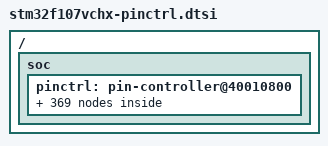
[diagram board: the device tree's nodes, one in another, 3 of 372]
/*
 * NOTE: Autogenerated file using genpinctrl.py
 *
 * SPDX-License-Identifier: Apache-2.0
 */

#include <zephyr/dt-bindings/pinctrl/stm32f1-pinctrl.h>

/ {
	soc {
		pinctrl: pin-controller@40010800 {

			/* ADC_IN */

			/omit-if-no-ref/ adc1_in0_pa0: adc1_in0_pa0 {
				pinmux = <STM32F1_PINMUX('A', 0, ANALOG, NO_REMAP)>;
			};

			/omit-if-no-ref/ adc1_in1_pa1: adc1_in1_pa1 {
				pinmux = <STM32F1_PINMUX('A', 1, ANALOG, NO_REMAP)>;
			};

			/omit-if-no-ref/ adc1_in2_pa2: adc1_in2_pa2 {
				pinmux = <STM32F1_PINMUX('A', 2, ANALOG, NO_REMAP)>;
			};

			/omit-if-no-ref/ adc1_in3_pa3: adc1_in3_pa3 {
				pinmux = <STM32F1_PINMUX('A', 3, ANALOG, NO_REMAP)>;
			};

			/omit-if-no-ref/ adc1_in4_pa4: adc1_in4_pa4 {
				pinmux = <STM32F1_PINMUX('A', 4, ANALOG, NO_REMAP)>;
			};

			/omit-if-no-ref/ adc1_in5_pa5: adc1_in5_pa5 {
				pinmux = <STM32F1_PINMUX('A', 5, ANALOG, NO_REMAP)>;
			};

			/omit-if-no-ref/ adc1_in6_pa6: adc1_in6_pa6 {
				pinmux = <STM32F1_PINMUX('A', 6, ANALOG, NO_REMAP)>;
			};

			/omit-if-no-ref/ adc1_in7_pa7: adc1_in7_pa7 {
				pinmux = <STM32F1_PINMUX('A', 7, ANALOG, NO_REMAP)>;
			};

			/omit-if-no-ref/ adc1_in8_pb0: adc1_in8_pb0 {
				pinmux = <STM32F1_PINMUX('B', 0, ANALOG, NO_REMAP)>;
			};

			/omit-if-no-ref/ adc1_in9_pb1: adc1_in9_pb1 {
				pinmux = <STM32F1_PINMUX('B', 1, ANALOG, NO_REMAP)>;
			};

			/omit-if-no-ref/ adc1_in10_pc0: adc1_in10_pc0 {
				pinmux = <STM32F1_PINMUX('C', 0, ANALOG, NO_REMAP)>;
			};

			/omit-if-no-ref/ adc1_in11_pc1: adc1_in11_pc1 {
				pinmux = <STM32F1_PINMUX('C', 1, ANALOG, NO_REMAP)>;
			};

			/omit-if-no-ref/ adc1_in12_pc2: adc1_in12_pc2 {
				pinmux = <STM32F1_PINMUX('C', 2, ANALOG, NO_REMAP)>;
			};

			/omit-if-no-ref/ adc1_in13_pc3: adc1_in13_pc3 {
				pinmux = <STM32F1_PINMUX('C', 3, ANALOG, NO_REMAP)>;
			};

			/omit-if-no-ref/ adc1_in14_pc4: adc1_in14_pc4 {
				pinmux = <STM32F1_PINMUX('C', 4, ANALOG, NO_REMAP)>;
			};

			/omit-if-no-ref/ adc1_in15_pc5: adc1_in15_pc5 {
				pinmux = <STM32F1_PINMUX('C', 5, ANALOG, NO_REMAP)>;
			};

			/omit-if-no-ref/ adc2_in0_pa0: adc2_in0_pa0 {
				pinmux = <STM32F1_PINMUX('A', 0, ANALOG, NO_REMAP)>;
			};

			/omit-if-no-ref/ adc2_in1_pa1: adc2_in1_pa1 {
				pinmux = <STM32F1_PINMUX('A', 1, ANALOG, NO_REMAP)>;
			};

			/omit-if-no-ref/ adc2_in2_pa2: adc2_in2_pa2 {
				pinmux = <STM32F1_PINMUX('A', 2, ANALOG, NO_REMAP)>;
			};

			/omit-if-no-ref/ adc2_in3_pa3: adc2_in3_pa3 {
				pinmux = <STM32F1_PINMUX('A', 3, ANALOG, NO_REMAP)>;
			};

			/omit-if-no-ref/ adc2_in4_pa4: adc2_in4_pa4 {
				pinmux = <STM32F1_PINMUX('A', 4, ANALOG, NO_REMAP)>;
			};

			/omit-if-no-ref/ adc2_in5_pa5: adc2_in5_pa5 {
				pinmux = <STM32F1_PINMUX('A', 5, ANALOG, NO_REMAP)>;
			};

			/omit-if-no-ref/ adc2_in6_pa6: adc2_in6_pa6 {
				pinmux = <STM32F1_PINMUX('A', 6, ANALOG, NO_REMAP)>;
			};

			/omit-if-no-ref/ adc2_in7_pa7: adc2_in7_pa7 {
				pinmux = <STM32F1_PINMUX('A', 7, ANALOG, NO_REMAP)>;
			};

			/omit-if-no-ref/ adc2_in8_pb0: adc2_in8_pb0 {
				pinmux = <STM32F1_PINMUX('B', 0, ANALOG, NO_REMAP)>;
			};

			/omit-if-no-ref/ adc2_in9_pb1: adc2_in9_pb1 {
				pinmux = <STM32F1_PINMUX('B', 1, ANALOG, NO_REMAP)>;
			};

			/omit-if-no-ref/ adc2_in10_pc0: adc2_in10_pc0 {
				pinmux = <STM32F1_PINMUX('C', 0, ANALOG, NO_REMAP)>;
			};

			/omit-if-no-ref/ adc2_in11_pc1: adc2_in11_pc1 {
				pinmux = <STM32F1_PINMUX('C', 1, ANALOG, NO_REMAP)>;
			};

			/omit-if-no-ref/ adc2_in12_pc2: adc2_in12_pc2 {
				pinmux = <STM32F1_PINMUX('C', 2, ANALOG, NO_REMAP)>;
			};

			/omit-if-no-ref/ adc2_in13_pc3: adc2_in13_pc3 {
				pinmux = <STM32F1_PINMUX('C', 3, ANALOG, NO_REMAP)>;
			};

			/omit-if-no-ref/ adc2_in14_pc4: adc2_in14_pc4 {
				pinmux = <STM32F1_PINMUX('C', 4, ANALOG, NO_REMAP)>;
			};

			/omit-if-no-ref/ adc2_in15_pc5: adc2_in15_pc5 {
				pinmux = <STM32F1_PINMUX('C', 5, ANALOG, NO_REMAP)>;
			};

			/* Analog */

			/omit-if-no-ref/ analog_pa0: analog_pa0 {
				pinmux = <STM32F1_PINMUX('A', 0, ANALOG, NO_REMAP)>;
			};

			/omit-if-no-ref/ analog_pa1: analog_pa1 {
				pinmux = <STM32F1_PINMUX('A', 1, ANALOG, NO_REMAP)>;
			};

			/omit-if-no-ref/ analog_pa2: analog_pa2 {
				pinmux = <STM32F1_PINMUX('A', 2, ANALOG, NO_REMAP)>;
			};

			/omit-if-no-ref/ analog_pa3: analog_pa3 {
				pinmux = <STM32F1_PINMUX('A', 3, ANALOG, NO_REMAP)>;
			};

			/omit-if-no-ref/ analog_pa4: analog_pa4 {
				pinmux = <STM32F1_PINMUX('A', 4, ANALOG, NO_REMAP)>;
			};

			/omit-if-no-ref/ analog_pa5: analog_pa5 {
				pinmux = <STM32F1_PINMUX('A', 5, ANALOG, NO_REMAP)>;
			};

			/omit-if-no-ref/ analog_pa6: analog_pa6 {
				pinmux = <STM32F1_PINMUX('A', 6, ANALOG, NO_REMAP)>;
			};

			/omit-if-no-ref/ analog_pa7: analog_pa7 {
				pinmux = <STM32F1_PINMUX('A', 7, ANALOG, NO_REMAP)>;
			};

			/omit-if-no-ref/ analog_pa8: analog_pa8 {
				pinmux = <STM32F1_PINMUX('A', 8, ANALOG, NO_REMAP)>;
			};

			/omit-if-no-ref/ analog_pa9: analog_pa9 {
				pinmux = <STM32F1_PINMUX('A', 9, ANALOG, NO_REMAP)>;
			};

			/omit-if-no-ref/ analog_pa10: analog_pa10 {
				pinmux = <STM32F1_PINMUX('A', 10, ANALOG, NO_REMAP)>;
			};

			/omit-if-no-ref/ analog_pa11: analog_pa11 {
				pinmux = <STM32F1_PINMUX('A', 11, ANALOG, NO_REMAP)>;
			};

			/omit-if-no-ref/ analog_pa12: analog_pa12 {
				pinmux = <STM32F1_PINMUX('A', 12, ANALOG, NO_REMAP)>;
			};

			/omit-if-no-ref/ analog_pa13: analog_pa13 {
				pinmux = <STM32F1_PINMUX('A', 13, ANALOG, NO_REMAP)>;
			};

			/omit-if-no-ref/ analog_pa14: analog_pa14 {
				pinmux = <STM32F1_PINMUX('A', 14, ANALOG, NO_REMAP)>;
			};

			/omit-if-no-ref/ analog_pa15: analog_pa15 {
				pinmux = <STM32F1_PINMUX('A', 15, ANALOG, NO_REMAP)>;
			};

			/omit-if-no-ref/ analog_pb0: analog_pb0 {
				pinmux = <STM32F1_PINMUX('B', 0, ANALOG, NO_REMAP)>;
			};

			/omit-if-no-ref/ analog_pb1: analog_pb1 {
				pinmux = <STM32F1_PINMUX('B', 1, ANALOG, NO_REMAP)>;
			};

			/omit-if-no-ref/ analog_pb2: analog_pb2 {
				pinmux = <STM32F1_PINMUX('B', 2, ANALOG, NO_REMAP)>;
			};

			/omit-if-no-ref/ analog_pb3: analog_pb3 {
				pinmux = <STM32F1_PINMUX('B', 3, ANALOG, NO_REMAP)>;
			};

			/omit-if-no-ref/ analog_pb4: analog_pb4 {
				pinmux = <STM32F1_PINMUX('B', 4, ANALOG, NO_REMAP)>;
			};

			/omit-if-no-ref/ analog_pb5: analog_pb5 {
				pinmux = <STM32F1_PINMUX('B', 5, ANALOG, NO_REMAP)>;
			};

			/omit-if-no-ref/ analog_pb6: analog_pb6 {
				pinmux = <STM32F1_PINMUX('B', 6, ANALOG, NO_REMAP)>;
			};

			/omit-if-no-ref/ analog_pb7: analog_pb7 {
				pinmux = <STM32F1_PINMUX('B', 7, ANALOG, NO_REMAP)>;
			};

			/omit-if-no-ref/ analog_pb8: analog_pb8 {
				pinmux = <STM32F1_PINMUX('B', 8, ANALOG, NO_REMAP)>;
			};

			/omit-if-no-ref/ analog_pb9: analog_pb9 {
				pinmux = <STM32F1_PINMUX('B', 9, ANALOG, NO_REMAP)>;
			};

			/omit-if-no-ref/ analog_pb10: analog_pb10 {
				pinmux = <STM32F1_PINMUX('B', 10, ANALOG, NO_REMAP)>;
			};

			/omit-if-no-ref/ analog_pb11: analog_pb11 {
				pinmux = <STM32F1_PINMUX('B', 11, ANALOG, NO_REMAP)>;
			};

			/omit-if-no-ref/ analog_pb12: analog_pb12 {
				pinmux = <STM32F1_PINMUX('B', 12, ANALOG, NO_REMAP)>;
			};

			/omit-if-no-ref/ analog_pb13: analog_pb13 {
				pinmux = <STM32F1_PINMUX('B', 13, ANALOG, NO_REMAP)>;
			};

			/omit-if-no-ref/ analog_pb14: analog_pb14 {
				pinmux = <STM32F1_PINMUX('B', 14, ANALOG, NO_REMAP)>;
			};

			/omit-if-no-ref/ analog_pb15: analog_pb15 {
				pinmux = <STM32F1_PINMUX('B', 15, ANALOG, NO_REMAP)>;
			};

			/omit-if-no-ref/ analog_pc0: analog_pc0 {
				pinmux = <STM32F1_PINMUX('C', 0, ANALOG, NO_REMAP)>;
			};

			/omit-if-no-ref/ analog_pc1: analog_pc1 {
				pinmux = <STM32F1_PINMUX('C', 1, ANALOG, NO_REMAP)>;
			};

			/omit-if-no-ref/ analog_pc2: analog_pc2 {
				pinmux = <STM32F1_PINMUX('C', 2, ANALOG, NO_REMAP)>;
			};

			/omit-if-no-ref/ analog_pc3: analog_pc3 {
				pinmux = <STM32F1_PINMUX('C', 3, ANALOG, NO_REMAP)>;
			};

			/omit-if-no-ref/ analog_pc4: analog_pc4 {
				pinmux = <STM32F1_PINMUX('C', 4, ANALOG, NO_REMAP)>;
			};

			/omit-if-no-ref/ analog_pc5: analog_pc5 {
				pinmux = <STM32F1_PINMUX('C', 5, ANALOG, NO_REMAP)>;
			};

			/omit-if-no-ref/ analog_pc6: analog_pc6 {
				pinmux = <STM32F1_PINMUX('C', 6, ANALOG, NO_REMAP)>;
			};

			/omit-if-no-ref/ analog_pc7: analog_pc7 {
				pinmux = <STM32F1_PINMUX('C', 7, ANALOG, NO_REMAP)>;
			};

			/omit-if-no-ref/ analog_pc8: analog_pc8 {
				pinmux = <STM32F1_PINMUX('C', 8, ANALOG, NO_REMAP)>;
			};

			/omit-if-no-ref/ analog_pc9: analog_pc9 {
				pinmux = <STM32F1_PINMUX('C', 9, ANALOG, NO_REMAP)>;
			};

			/omit-if-no-ref/ analog_pc10: analog_pc10 {
				pinmux = <STM32F1_PINMUX('C', 10, ANALOG, NO_REMAP)>;
			};

			/omit-if-no-ref/ analog_pc11: analog_pc11 {
				pinmux = <STM32F1_PINMUX('C', 11, ANALOG, NO_REMAP)>;
			};

			/omit-if-no-ref/ analog_pc12: analog_pc12 {
				pinmux = <STM32F1_PINMUX('C', 12, ANALOG, NO_REMAP)>;
			};

			/omit-if-no-ref/ analog_pc13: analog_pc13 {
				pinmux = <STM32F1_PINMUX('C', 13, ANALOG, NO_REMAP)>;
			};

			/omit-if-no-ref/ analog_pc14: analog_pc14 {
				pinmux = <STM32F1_PINMUX('C', 14, ANALOG, NO_REMAP)>;
			};

			/omit-if-no-ref/ analog_pc15: analog_pc15 {
				pinmux = <STM32F1_PINMUX('C', 15, ANALOG, NO_REMAP)>;
			};

			/omit-if-no-ref/ analog_pd0: analog_pd0 {
				pinmux = <STM32F1_PINMUX('D', 0, ANALOG, NO_REMAP)>;
			};

			/omit-if-no-ref/ analog_pd1: analog_pd1 {
				pinmux = <STM32F1_PINMUX('D', 1, ANALOG, NO_REMAP)>;
			};

			/omit-if-no-ref/ analog_pd2: analog_pd2 {
				pinmux = <STM32F1_PINMUX('D', 2, ANALOG, NO_REMAP)>;
			};

			/omit-if-no-ref/ analog_pd3: analog_pd3 {
				pinmux = <STM32F1_PINMUX('D', 3, ANALOG, NO_REMAP)>;
			};

			/omit-if-no-ref/ analog_pd4: analog_pd4 {
				pinmux = <STM32F1_PINMUX('D', 4, ANALOG, NO_REMAP)>;
			};

			/omit-if-no-ref/ analog_pd5: analog_pd5 {
				pinmux = <STM32F1_PINMUX('D', 5, ANALOG, NO_REMAP)>;
			};

			/omit-if-no-ref/ analog_pd6: analog_pd6 {
				pinmux = <STM32F1_PINMUX('D', 6, ANALOG, NO_REMAP)>;
			};

			/omit-if-no-ref/ analog_pd7: analog_pd7 {
				pinmux = <STM32F1_PINMUX('D', 7, ANALOG, NO_REMAP)>;
			};

			/omit-if-no-ref/ analog_pd8: analog_pd8 {
				pinmux = <STM32F1_PINMUX('D', 8, ANALOG, NO_REMAP)>;
			};

			/omit-if-no-ref/ analog_pd9: analog_pd9 {
				pinmux = <STM32F1_PINMUX('D', 9, ANALOG, NO_REMAP)>;
			};

			/omit-if-no-ref/ analog_pd10: analog_pd10 {
				pinmux = <STM32F1_PINMUX('D', 10, ANALOG, NO_REMAP)>;
			};

			/omit-if-no-ref/ analog_pd11: analog_pd11 {
				pinmux = <STM32F1_PINMUX('D', 11, ANALOG, NO_REMAP)>;
			};

			/omit-if-no-ref/ analog_pd12: analog_pd12 {
				pinmux = <STM32F1_PINMUX('D', 12, ANALOG, NO_REMAP)>;
			};

			/omit-if-no-ref/ analog_pd13: analog_pd13 {
				pinmux = <STM32F1_PINMUX('D', 13, ANALOG, NO_REMAP)>;
			};

			/omit-if-no-ref/ analog_pd14: analog_pd14 {
				pinmux = <STM32F1_PINMUX('D', 14, ANALOG, NO_REMAP)>;
			};

			/omit-if-no-ref/ analog_pd15: analog_pd15 {
				pinmux = <STM32F1_PINMUX('D', 15, ANALOG, NO_REMAP)>;
			};

			/omit-if-no-ref/ analog_pe0: analog_pe0 {
				pinmux = <STM32F1_PINMUX('E', 0, ANALOG, NO_REMAP)>;
			};

			/omit-if-no-ref/ analog_pe1: analog_pe1 {
				pinmux = <STM32F1_PINMUX('E', 1, ANALOG, NO_REMAP)>;
			};

			/omit-if-no-ref/ analog_pe2: analog_pe2 {
				pinmux = <STM32F1_PINMUX('E', 2, ANALOG, NO_REMAP)>;
			};

			/omit-if-no-ref/ analog_pe3: analog_pe3 {
				pinmux = <STM32F1_PINMUX('E', 3, ANALOG, NO_REMAP)>;
			};

			/omit-if-no-ref/ analog_pe4: analog_pe4 {
				pinmux = <STM32F1_PINMUX('E', 4, ANALOG, NO_REMAP)>;
			};

			/omit-if-no-ref/ analog_pe5: analog_pe5 {
				pinmux = <STM32F1_PINMUX('E', 5, ANALOG, NO_REMAP)>;
			};

			/omit-if-no-ref/ analog_pe6: analog_pe6 {
				pinmux = <STM32F1_PINMUX('E', 6, ANALOG, NO_REMAP)>;
			};

			/omit-if-no-ref/ analog_pe7: analog_pe7 {
				pinmux = <STM32F1_PINMUX('E', 7, ANALOG, NO_REMAP)>;
			};

			/omit-if-no-ref/ analog_pe8: analog_pe8 {
				pinmux = <STM32F1_PINMUX('E', 8, ANALOG, NO_REMAP)>;
			};

			/omit-if-no-ref/ analog_pe9: analog_pe9 {
				pinmux = <STM32F1_PINMUX('E', 9, ANALOG, NO_REMAP)>;
			};

			/omit-if-no-ref/ analog_pe10: analog_pe10 {
				pinmux = <STM32F1_PINMUX('E', 10, ANALOG, NO_REMAP)>;
			};

			/omit-if-no-ref/ analog_pe11: analog_pe11 {
				pinmux = <STM32F1_PINMUX('E', 11, ANALOG, NO_REMAP)>;
			};

			/omit-if-no-ref/ analog_pe12: analog_pe12 {
				pinmux = <STM32F1_PINMUX('E', 12, ANALOG, NO_REMAP)>;
			};

			/omit-if-no-ref/ analog_pe13: analog_pe13 {
				pinmux = <STM32F1_PINMUX('E', 13, ANALOG, NO_REMAP)>;
			};

			/omit-if-no-ref/ analog_pe14: analog_pe14 {
				pinmux = <STM32F1_PINMUX('E', 14, ANALOG, NO_REMAP)>;
			};

			/omit-if-no-ref/ analog_pe15: analog_pe15 {
				pinmux = <STM32F1_PINMUX('E', 15, ANALOG, NO_REMAP)>;
			};

			/* CAN_RX */

			/omit-if-no-ref/ can1_rx_pa11: can1_rx_pa11 {
				pinmux = <STM32F1_PINMUX('A', 11, GPIO_IN, CAN1_REMAP0)>;
			};

			/omit-if-no-ref/ can1_rx_remap1_pb8: can1_rx_remap1_pb8 {
				pinmux = <STM32F1_PINMUX('B', 8, GPIO_IN, CAN1_REMAP1)>;
			};

			/omit-if-no-ref/ can1_rx_remap2_pd0: can1_rx_remap2_pd0 {
				pinmux = <STM32F1_PINMUX('D', 0, GPIO_IN, CAN1_REMAP2)>;
			};

			/omit-if-no-ref/ can2_rx_remap1_pb5: can2_rx_remap1_pb5 {
				pinmux = <STM32F1_PINMUX('B', 5, GPIO_IN, CAN2_REMAP1)>;
			};

			/omit-if-no-ref/ can2_rx_pb12: can2_rx_pb12 {
				pinmux = <STM32F1_PINMUX('B', 12, GPIO_IN, CAN2_REMAP0)>;
			};

			/* CAN_TX */

			/omit-if-no-ref/ can1_tx_pa12: can1_tx_pa12 {
				pinmux = <STM32F1_PINMUX('A', 12, ALTERNATE, CAN1_REMAP0)>;
			};

			/omit-if-no-ref/ can1_tx_remap1_pb9: can1_tx_remap1_pb9 {
				pinmux = <STM32F1_PINMUX('B', 9, ALTERNATE, CAN1_REMAP1)>;
			};

			/omit-if-no-ref/ can1_tx_remap2_pd1: can1_tx_remap2_pd1 {
				pinmux = <STM32F1_PINMUX('D', 1, ALTERNATE, CAN1_REMAP2)>;
			};

			/omit-if-no-ref/ can2_tx_remap1_pb6: can2_tx_remap1_pb6 {
				pinmux = <STM32F1_PINMUX('B', 6, ALTERNATE, CAN2_REMAP1)>;
			};

			/omit-if-no-ref/ can2_tx_pb13: can2_tx_pb13 {
				pinmux = <STM32F1_PINMUX('B', 13, ALTERNATE, CAN2_REMAP0)>;
			};

			/* DAC_OUT */

			/omit-if-no-ref/ dac_out1_pa4: dac_out1_pa4 {
				pinmux = <STM32F1_PINMUX('A', 4, ANALOG, NO_REMAP)>;
			};

			/omit-if-no-ref/ dac_out2_pa5: dac_out2_pa5 {
				pinmux = <STM32F1_PINMUX('A', 5, ANALOG, NO_REMAP)>;
			};

			/* ETH_COL */

			/omit-if-no-ref/ eth_col_pa3: eth_col_pa3 {
				pinmux = <STM32F1_PINMUX('A', 3, GPIO_IN, NO_REMAP)>;
			};

			/* ETH_CRS */

			/omit-if-no-ref/ eth_crs_pa0: eth_crs_pa0 {
				pinmux = <STM32F1_PINMUX('A', 0, GPIO_IN, NO_REMAP)>;
			};

			/* ETH_CRS_DV */

			/omit-if-no-ref/ eth_crs_dv_pa7: eth_crs_dv_pa7 {
				pinmux = <STM32F1_PINMUX('A', 7, GPIO_IN, ETH_REMAP0)>;
			};

			/omit-if-no-ref/ eth_crs_dv_remap1_pd8: eth_crs_dv_remap1_pd8 {
				pinmux = <STM32F1_PINMUX('D', 8, GPIO_IN, ETH_REMAP1)>;
			};

			/* ETH_MDC */

			/omit-if-no-ref/ eth_mdc_pc1: eth_mdc_pc1 {
				pinmux = <STM32F1_PINMUX('C', 1, ALTERNATE, NO_REMAP)>;
				slew-rate = "max-speed-50mhz";
			};

			/* ETH_MDIO */

			/omit-if-no-ref/ eth_mdio_pa2: eth_mdio_pa2 {
				pinmux = <STM32F1_PINMUX('A', 2, ALTERNATE, NO_REMAP)>;
				slew-rate = "max-speed-50mhz";
			};

			/* ETH_PPS_OUT */

			/omit-if-no-ref/ eth_pps_out_pb5: eth_pps_out_pb5 {
				pinmux = <STM32F1_PINMUX('B', 5, ALTERNATE, NO_REMAP)>;
				slew-rate = "max-speed-50mhz";
			};

			/* ETH_REF_CLK */

			/omit-if-no-ref/ eth_ref_clk_pa1: eth_ref_clk_pa1 {
				pinmux = <STM32F1_PINMUX('A', 1, GPIO_IN, NO_REMAP)>;
			};

			/* ETH_RXD0 */

			/omit-if-no-ref/ eth_rxd0_pc4: eth_rxd0_pc4 {
				pinmux = <STM32F1_PINMUX('C', 4, GPIO_IN, ETH_REMAP0)>;
			};

			/omit-if-no-ref/ eth_rxd0_remap1_pd9: eth_rxd0_remap1_pd9 {
				pinmux = <STM32F1_PINMUX('D', 9, GPIO_IN, ETH_REMAP1)>;
			};

			/* ETH_RXD1 */

			/omit-if-no-ref/ eth_rxd1_pc5: eth_rxd1_pc5 {
				pinmux = <STM32F1_PINMUX('C', 5, GPIO_IN, ETH_REMAP0)>;
			};

			/omit-if-no-ref/ eth_rxd1_remap1_pd10: eth_rxd1_remap1_pd10 {
				pinmux = <STM32F1_PINMUX('D', 10, GPIO_IN, ETH_REMAP1)>;
			};

			/* ETH_RXD2 */

			/omit-if-no-ref/ eth_rxd2_pb0: eth_rxd2_pb0 {
				pinmux = <STM32F1_PINMUX('B', 0, GPIO_IN, ETH_REMAP0)>;
			};

			/omit-if-no-ref/ eth_rxd2_remap1_pd11: eth_rxd2_remap1_pd11 {
				pinmux = <STM32F1_PINMUX('D', 11, GPIO_IN, ETH_REMAP1)>;
			};

			/* ETH_RXD3 */

			/omit-if-no-ref/ eth_rxd3_pb1: eth_rxd3_pb1 {
				pinmux = <STM32F1_PINMUX('B', 1, GPIO_IN, ETH_REMAP0)>;
			};

			/omit-if-no-ref/ eth_rxd3_remap1_pd12: eth_rxd3_remap1_pd12 {
				pinmux = <STM32F1_PINMUX('D', 12, GPIO_IN, ETH_REMAP1)>;
			};

			/* ETH_RX_CLK */

			/omit-if-no-ref/ eth_rx_clk_pa1: eth_rx_clk_pa1 {
				pinmux = <STM32F1_PINMUX('A', 1, GPIO_IN, NO_REMAP)>;
			};

			/* ETH_RX_DV */

			/omit-if-no-ref/ eth_rx_dv_pa7: eth_rx_dv_pa7 {
				pinmux = <STM32F1_PINMUX('A', 7, GPIO_IN, ETH_REMAP0)>;
			};

			/omit-if-no-ref/ eth_rx_dv_remap1_pd8: eth_rx_dv_remap1_pd8 {
				pinmux = <STM32F1_PINMUX('D', 8, GPIO_IN, ETH_REMAP1)>;
			};

			/* ETH_RX_ER */

			/omit-if-no-ref/ eth_rx_er_pb10: eth_rx_er_pb10 {
				pinmux = <STM32F1_PINMUX('B', 10, GPIO_IN, NO_REMAP)>;
			};

			/* ETH_TXD0 */

			/omit-if-no-ref/ eth_txd0_pb12: eth_txd0_pb12 {
				pinmux = <STM32F1_PINMUX('B', 12, ALTERNATE, NO_REMAP)>;
				slew-rate = "max-speed-50mhz";
			};

			/* ETH_TXD1 */

			/omit-if-no-ref/ eth_txd1_pb13: eth_txd1_pb13 {
				pinmux = <STM32F1_PINMUX('B', 13, ALTERNATE, NO_REMAP)>;
				slew-rate = "max-speed-50mhz";
			};

			/* ETH_TXD2 */

			/omit-if-no-ref/ eth_txd2_pc2: eth_txd2_pc2 {
				pinmux = <STM32F1_PINMUX('C', 2, ALTERNATE, NO_REMAP)>;
				slew-rate = "max-speed-50mhz";
			};

			/* ETH_TXD3 */

			/omit-if-no-ref/ eth_txd3_pb8: eth_txd3_pb8 {
				pinmux = <STM32F1_PINMUX('B', 8, ALTERNATE, NO_REMAP)>;
				slew-rate = "max-speed-50mhz";
			};

			/* ETH_TX_CLK */

			/omit-if-no-ref/ eth_tx_clk_pc3: eth_tx_clk_pc3 {
				pinmux = <STM32F1_PINMUX('C', 3, GPIO_IN, NO_REMAP)>;
			};

			/* ETH_TX_EN */

			/omit-if-no-ref/ eth_tx_en_pb11: eth_tx_en_pb11 {
				pinmux = <STM32F1_PINMUX('B', 11, ALTERNATE, NO_REMAP)>;
				slew-rate = "max-speed-50mhz";
			};

			/* I2C_SCL */

			/omit-if-no-ref/ i2c1_scl_pb6: i2c1_scl_pb6 {
				pinmux = <STM32F1_PINMUX('B', 6, ALTERNATE, I2C1_REMAP0)>;
				drive-open-drain;
			};

			/omit-if-no-ref/ i2c1_scl_remap1_pb8: i2c1_scl_remap1_pb8 {
				pinmux = <STM32F1_PINMUX('B', 8, ALTERNATE, I2C1_REMAP1)>;
				drive-open-drain;
			};

			/* I2C_SDA */

			/omit-if-no-ref/ i2c1_sda_pb7: i2c1_sda_pb7 {
				pinmux = <STM32F1_PINMUX('B', 7, ALTERNATE, I2C1_REMAP0)>;
				drive-open-drain;
			};

			/omit-if-no-ref/ i2c1_sda_remap1_pb9: i2c1_sda_remap1_pb9 {
				pinmux = <STM32F1_PINMUX('B', 9, ALTERNATE, I2C1_REMAP1)>;
				drive-open-drain;
			};

			/* I2C_SMBA */

			/omit-if-no-ref/ i2c1_smba_pb5: i2c1_smba_pb5 {
				pinmux = <STM32F1_PINMUX('B', 5, ALTERNATE, NO_REMAP)>;
			};

			/* I2S_CK */

			/omit-if-no-ref/ i2s2_ck_pb13: i2s2_ck_pb13 {
				pinmux = <STM32F1_PINMUX('B', 13, ALTERNATE, NO_REMAP)>;
			};

			/omit-if-no-ref/ i2s3_ck_pb3: i2s3_ck_pb3 {
				pinmux = <STM32F1_PINMUX('B', 3, ALTERNATE, I2S3_REMAP0)>;
			};

			/omit-if-no-ref/ i2s3_ck_remap1_pc10: i2s3_ck_remap1_pc10 {
				pinmux = <STM32F1_PINMUX('C', 10, ALTERNATE, I2S3_REMAP1)>;
			};

			/* I2S_SD */

			/omit-if-no-ref/ i2s2_sd_pb15: i2s2_sd_pb15 {
				pinmux = <STM32F1_PINMUX('B', 15, ALTERNATE, NO_REMAP)>;
			};

			/omit-if-no-ref/ i2s3_sd_pb5: i2s3_sd_pb5 {
				pinmux = <STM32F1_PINMUX('B', 5, ALTERNATE, I2S3_REMAP0)>;
			};

			/omit-if-no-ref/ i2s3_sd_remap1_pc12: i2s3_sd_remap1_pc12 {
				pinmux = <STM32F1_PINMUX('C', 12, ALTERNATE, I2S3_REMAP1)>;
			};

			/* I2S_WS */

			/omit-if-no-ref/ i2s2_ws_pb12: i2s2_ws_pb12 {
				pinmux = <STM32F1_PINMUX('B', 12, ALTERNATE, NO_REMAP)>;
			};

			/omit-if-no-ref/ i2s3_ws_remap1_pa4: i2s3_ws_remap1_pa4 {
				pinmux = <STM32F1_PINMUX('A', 4, ALTERNATE, I2S3_REMAP1)>;
			};

			/omit-if-no-ref/ i2s3_ws_pa15: i2s3_ws_pa15 {
				pinmux = <STM32F1_PINMUX('A', 15, ALTERNATE, I2S3_REMAP0)>;
			};

			/* JTAG PORT */

			/omit-if-no-ref/ sys_jtms_swdio_pa13: sys_jtms_swdio_pa13 {
				pinmux = <STM32F1_PINMUX('A', 13, ALTERNATE, NO_REMAP)>;
			};

			/omit-if-no-ref/ sys_jtck_swclk_pa14: sys_jtck_swclk_pa14 {
				pinmux = <STM32F1_PINMUX('A', 14, ALTERNATE, NO_REMAP)>;
			};

			/omit-if-no-ref/ sys_jtdi_pa15: sys_jtdi_pa15 {
				pinmux = <STM32F1_PINMUX('A', 15, ALTERNATE, NO_REMAP)>;
			};

			/omit-if-no-ref/ sys_jtdo_pb3: sys_jtdo_pb3 {
				pinmux = <STM32F1_PINMUX('B', 3, ALTERNATE, NO_REMAP)>;
			};

			/* RCC_MCO */

			/omit-if-no-ref/ rcc_mco_pa8: rcc_mco_pa8 {
				pinmux = <STM32F1_PINMUX('A', 8, ALTERNATE, NO_REMAP)>;
			};

			/* SPI_MASTER_MISO */

			/omit-if-no-ref/ spi1_miso_master_pa6: spi1_miso_master_pa6 {
				pinmux = <STM32F1_PINMUX('A', 6, GPIO_IN, SPI1_REMAP0)>;
				bias-pull-down;
			};

			/omit-if-no-ref/ spi1_miso_remap1_master_pb4: spi1_miso_remap1_master_pb4 {
				pinmux = <STM32F1_PINMUX('B', 4, GPIO_IN, SPI1_REMAP1)>;
				bias-pull-down;
			};

			/omit-if-no-ref/ spi2_miso_master_pb14: spi2_miso_master_pb14 {
				pinmux = <STM32F1_PINMUX('B', 14, GPIO_IN, NO_REMAP)>;
				bias-pull-down;
			};

			/omit-if-no-ref/ spi3_miso_master_pb4: spi3_miso_master_pb4 {
				pinmux = <STM32F1_PINMUX('B', 4, GPIO_IN, SPI3_REMAP0)>;
				bias-pull-down;
			};

			/omit-if-no-ref/ spi3_miso_remap1_master_pc11: spi3_miso_remap1_master_pc11 {
				pinmux = <STM32F1_PINMUX('C', 11, GPIO_IN, SPI3_REMAP1)>;
				bias-pull-down;
			};

			/* SPI_MASTER_MOSI */

			/omit-if-no-ref/ spi1_mosi_master_pa7: spi1_mosi_master_pa7 {
				pinmux = <STM32F1_PINMUX('A', 7, ALTERNATE, SPI1_REMAP0)>;
			};

			/omit-if-no-ref/ spi1_mosi_remap1_master_pb5: spi1_mosi_remap1_master_pb5 {
				pinmux = <STM32F1_PINMUX('B', 5, ALTERNATE, SPI1_REMAP1)>;
			};

			/omit-if-no-ref/ spi2_mosi_master_pb15: spi2_mosi_master_pb15 {
				pinmux = <STM32F1_PINMUX('B', 15, ALTERNATE, NO_REMAP)>;
			};

			/omit-if-no-ref/ spi3_mosi_master_pb5: spi3_mosi_master_pb5 {
				pinmux = <STM32F1_PINMUX('B', 5, ALTERNATE, SPI3_REMAP0)>;
			};

			/omit-if-no-ref/ spi3_mosi_remap1_master_pc12: spi3_mosi_remap1_master_pc12 {
				pinmux = <STM32F1_PINMUX('C', 12, ALTERNATE, SPI3_REMAP1)>;
			};

			/* SPI_MASTER_NSS */

			/omit-if-no-ref/ spi1_nss_master_pa4: spi1_nss_master_pa4 {
				pinmux = <STM32F1_PINMUX('A', 4, ALTERNATE, SPI1_REMAP0)>;
			};

			/omit-if-no-ref/ spi1_nss_remap1_master_pa15: spi1_nss_remap1_master_pa15 {
				pinmux = <STM32F1_PINMUX('A', 15, ALTERNATE, SPI1_REMAP1)>;
			};

			/omit-if-no-ref/ spi2_nss_master_pb12: spi2_nss_master_pb12 {
				pinmux = <STM32F1_PINMUX('B', 12, ALTERNATE, NO_REMAP)>;
			};

			/omit-if-no-ref/ spi3_nss_remap1_master_pa4: spi3_nss_remap1_master_pa4 {
				pinmux = <STM32F1_PINMUX('A', 4, ALTERNATE, SPI3_REMAP1)>;
			};

			/omit-if-no-ref/ spi3_nss_master_pa15: spi3_nss_master_pa15 {
				pinmux = <STM32F1_PINMUX('A', 15, ALTERNATE, SPI3_REMAP0)>;
			};

			/* SPI_MASTER_SCK */

			/omit-if-no-ref/ spi1_sck_master_pa5: spi1_sck_master_pa5 {
				pinmux = <STM32F1_PINMUX('A', 5, ALTERNATE, SPI1_REMAP0)>;
			};

			/omit-if-no-ref/ spi1_sck_remap1_master_pb3: spi1_sck_remap1_master_pb3 {
				pinmux = <STM32F1_PINMUX('B', 3, ALTERNATE, SPI1_REMAP1)>;
			};

			/omit-if-no-ref/ spi2_sck_master_pb13: spi2_sck_master_pb13 {
				pinmux = <STM32F1_PINMUX('B', 13, ALTERNATE, NO_REMAP)>;
			};

			/omit-if-no-ref/ spi3_sck_master_pb3: spi3_sck_master_pb3 {
				pinmux = <STM32F1_PINMUX('B', 3, ALTERNATE, SPI3_REMAP0)>;
			};

			/omit-if-no-ref/ spi3_sck_remap1_master_pc10: spi3_sck_remap1_master_pc10 {
				pinmux = <STM32F1_PINMUX('C', 10, ALTERNATE, SPI3_REMAP1)>;
			};

			/* SPI_SLAVE_MISO */

			/omit-if-no-ref/ spi1_miso_slave_pa6: spi1_miso_slave_pa6 {
				pinmux = <STM32F1_PINMUX('A', 6, ALTERNATE, SPI1_REMAP0)>;
			};

			/omit-if-no-ref/ spi1_miso_remap1_slave_pb4: spi1_miso_remap1_slave_pb4 {
				pinmux = <STM32F1_PINMUX('B', 4, ALTERNATE, SPI1_REMAP1)>;
			};

			/omit-if-no-ref/ spi2_miso_slave_pb14: spi2_miso_slave_pb14 {
				pinmux = <STM32F1_PINMUX('B', 14, ALTERNATE, NO_REMAP)>;
			};

			/omit-if-no-ref/ spi3_miso_slave_pb4: spi3_miso_slave_pb4 {
				pinmux = <STM32F1_PINMUX('B', 4, ALTERNATE, SPI3_REMAP0)>;
			};

			/omit-if-no-ref/ spi3_miso_remap1_slave_pc11: spi3_miso_remap1_slave_pc11 {
				pinmux = <STM32F1_PINMUX('C', 11, ALTERNATE, SPI3_REMAP1)>;
			};

			/* SPI_SLAVE_MOSI */

			/omit-if-no-ref/ spi1_mosi_slave_pa7: spi1_mosi_slave_pa7 {
				pinmux = <STM32F1_PINMUX('A', 7, GPIO_IN, SPI1_REMAP0)>;
			};

			/omit-if-no-ref/ spi1_mosi_remap1_slave_pb5: spi1_mosi_remap1_slave_pb5 {
				pinmux = <STM32F1_PINMUX('B', 5, GPIO_IN, SPI1_REMAP1)>;
			};

			/omit-if-no-ref/ spi2_mosi_slave_pb15: spi2_mosi_slave_pb15 {
				pinmux = <STM32F1_PINMUX('B', 15, GPIO_IN, NO_REMAP)>;
			};

			/omit-if-no-ref/ spi3_mosi_slave_pb5: spi3_mosi_slave_pb5 {
				pinmux = <STM32F1_PINMUX('B', 5, GPIO_IN, SPI3_REMAP0)>;
			};

			/omit-if-no-ref/ spi3_mosi_remap1_slave_pc12: spi3_mosi_remap1_slave_pc12 {
				pinmux = <STM32F1_PINMUX('C', 12, GPIO_IN, SPI3_REMAP1)>;
			};

			/* SPI_SLAVE_NSS */

			/omit-if-no-ref/ spi1_nss_slave_pa4: spi1_nss_slave_pa4 {
				pinmux = <STM32F1_PINMUX('A', 4, GPIO_IN, SPI1_REMAP0)>;
				bias-pull-up;
			};

			/omit-if-no-ref/ spi1_nss_remap1_slave_pa15: spi1_nss_remap1_slave_pa15 {
				pinmux = <STM32F1_PINMUX('A', 15, GPIO_IN, SPI1_REMAP1)>;
				bias-pull-up;
			};

			/omit-if-no-ref/ spi2_nss_slave_pb12: spi2_nss_slave_pb12 {
				pinmux = <STM32F1_PINMUX('B', 12, GPIO_IN, NO_REMAP)>;
				bias-pull-up;
			};

			/omit-if-no-ref/ spi3_nss_remap1_slave_pa4: spi3_nss_remap1_slave_pa4 {
				pinmux = <STM32F1_PINMUX('A', 4, GPIO_IN, SPI3_REMAP1)>;
				bias-pull-up;
			};

			/omit-if-no-ref/ spi3_nss_slave_pa15: spi3_nss_slave_pa15 {
				pinmux = <STM32F1_PINMUX('A', 15, GPIO_IN, SPI3_REMAP0)>;
				bias-pull-up;
			};

			/* SPI_SLAVE_SCK */

			/omit-if-no-ref/ spi1_sck_slave_pa5: spi1_sck_slave_pa5 {
				pinmux = <STM32F1_PINMUX('A', 5, GPIO_IN, SPI1_REMAP0)>;
			};

			/omit-if-no-ref/ spi1_sck_remap1_slave_pb3: spi1_sck_remap1_slave_pb3 {
				pinmux = <STM32F1_PINMUX('B', 3, GPIO_IN, SPI1_REMAP1)>;
			};

			/omit-if-no-ref/ spi2_sck_slave_pb13: spi2_sck_slave_pb13 {
				pinmux = <STM32F1_PINMUX('B', 13, GPIO_IN, NO_REMAP)>;
			};

			/omit-if-no-ref/ spi3_sck_slave_pb3: spi3_sck_slave_pb3 {
				pinmux = <STM32F1_PINMUX('B', 3, GPIO_IN, SPI3_REMAP0)>;
			};

			/omit-if-no-ref/ spi3_sck_remap1_slave_pc10: spi3_sck_remap1_slave_pc10 {
				pinmux = <STM32F1_PINMUX('C', 10, GPIO_IN, SPI3_REMAP1)>;
			};

			/* TIM_BKIN */

			/omit-if-no-ref/ tim1_bkin_remap1_pa6: tim1_bkin_remap1_pa6 {
				pinmux = <STM32F1_PINMUX('A', 6, GPIO_IN, TIM1_REMAP1)>;
			};

			/omit-if-no-ref/ tim1_bkin_pb12: tim1_bkin_pb12 {
				pinmux = <STM32F1_PINMUX('B', 12, GPIO_IN, TIM1_REMAP0)>;
			};

			/omit-if-no-ref/ tim1_bkin_remap2_pe15: tim1_bkin_remap2_pe15 {
				pinmux = <STM32F1_PINMUX('E', 15, GPIO_IN, TIM1_REMAP2)>;
			};

			/* TIM_CH_PWM_IN / TIM_CHN_PWM_IN */

			/omit-if-no-ref/ tim1_ch1n_remap1_pwm_in_pa7: tim1_ch1n_remap1_pwm_in_pa7 {
				pinmux = <STM32F1_PINMUX('A', 7, GPIO_IN, TIM1_REMAP1)>;
			};

			/omit-if-no-ref/ tim1_ch1_pwm_in_pa8: tim1_ch1_pwm_in_pa8 {
				pinmux = <STM32F1_PINMUX('A', 8, GPIO_IN, TIM1_REMAP0)>;
			};

			/omit-if-no-ref/ tim1_ch1_remap1_pwm_in_pa8: tim1_ch1_remap1_pwm_in_pa8 {
				pinmux = <STM32F1_PINMUX('A', 8, GPIO_IN, TIM1_REMAP1)>;
			};

			/omit-if-no-ref/ tim1_ch2_pwm_in_pa9: tim1_ch2_pwm_in_pa9 {
				pinmux = <STM32F1_PINMUX('A', 9, GPIO_IN, TIM1_REMAP0)>;
			};

			/omit-if-no-ref/ tim1_ch2_remap1_pwm_in_pa9: tim1_ch2_remap1_pwm_in_pa9 {
				pinmux = <STM32F1_PINMUX('A', 9, GPIO_IN, TIM1_REMAP1)>;
			};

			/omit-if-no-ref/ tim1_ch3_pwm_in_pa10: tim1_ch3_pwm_in_pa10 {
				pinmux = <STM32F1_PINMUX('A', 10, GPIO_IN, TIM1_REMAP0)>;
			};

			/omit-if-no-ref/ tim1_ch3_remap1_pwm_in_pa10: tim1_ch3_remap1_pwm_in_pa10 {
				pinmux = <STM32F1_PINMUX('A', 10, GPIO_IN, TIM1_REMAP1)>;
			};

			/omit-if-no-ref/ tim1_ch4_pwm_in_pa11: tim1_ch4_pwm_in_pa11 {
				pinmux = <STM32F1_PINMUX('A', 11, GPIO_IN, TIM1_REMAP0)>;
			};

			/omit-if-no-ref/ tim1_ch4_remap1_pwm_in_pa11: tim1_ch4_remap1_pwm_in_pa11 {
				pinmux = <STM32F1_PINMUX('A', 11, GPIO_IN, TIM1_REMAP1)>;
			};

			/omit-if-no-ref/ tim1_ch2n_remap1_pwm_in_pb0: tim1_ch2n_remap1_pwm_in_pb0 {
				pinmux = <STM32F1_PINMUX('B', 0, GPIO_IN, TIM1_REMAP1)>;
			};

			/omit-if-no-ref/ tim1_ch3n_remap1_pwm_in_pb1: tim1_ch3n_remap1_pwm_in_pb1 {
				pinmux = <STM32F1_PINMUX('B', 1, GPIO_IN, TIM1_REMAP1)>;
			};

			/omit-if-no-ref/ tim1_ch1n_pwm_in_pb13: tim1_ch1n_pwm_in_pb13 {
				pinmux = <STM32F1_PINMUX('B', 13, GPIO_IN, TIM1_REMAP0)>;
			};

			/omit-if-no-ref/ tim1_ch2n_pwm_in_pb14: tim1_ch2n_pwm_in_pb14 {
				pinmux = <STM32F1_PINMUX('B', 14, GPIO_IN, TIM1_REMAP0)>;
			};

			/omit-if-no-ref/ tim1_ch3n_pwm_in_pb15: tim1_ch3n_pwm_in_pb15 {
				pinmux = <STM32F1_PINMUX('B', 15, GPIO_IN, TIM1_REMAP0)>;
			};

			/omit-if-no-ref/ tim1_ch1n_remap2_pwm_in_pe8: tim1_ch1n_remap2_pwm_in_pe8 {
				pinmux = <STM32F1_PINMUX('E', 8, GPIO_IN, TIM1_REMAP2)>;
			};

			/omit-if-no-ref/ tim1_ch1_remap2_pwm_in_pe9: tim1_ch1_remap2_pwm_in_pe9 {
				pinmux = <STM32F1_PINMUX('E', 9, GPIO_IN, TIM1_REMAP2)>;
			};

			/omit-if-no-ref/ tim1_ch2n_remap2_pwm_in_pe10: tim1_ch2n_remap2_pwm_in_pe10 {
				pinmux = <STM32F1_PINMUX('E', 10, GPIO_IN, TIM1_REMAP2)>;
			};

			/omit-if-no-ref/ tim1_ch2_remap2_pwm_in_pe11: tim1_ch2_remap2_pwm_in_pe11 {
				pinmux = <STM32F1_PINMUX('E', 11, GPIO_IN, TIM1_REMAP2)>;
			};

			/omit-if-no-ref/ tim1_ch3n_remap2_pwm_in_pe12: tim1_ch3n_remap2_pwm_in_pe12 {
				pinmux = <STM32F1_PINMUX('E', 12, GPIO_IN, TIM1_REMAP2)>;
			};

			/omit-if-no-ref/ tim1_ch3_remap2_pwm_in_pe13: tim1_ch3_remap2_pwm_in_pe13 {
				pinmux = <STM32F1_PINMUX('E', 13, GPIO_IN, TIM1_REMAP2)>;
			};

			/omit-if-no-ref/ tim1_ch4_remap2_pwm_in_pe14: tim1_ch4_remap2_pwm_in_pe14 {
				pinmux = <STM32F1_PINMUX('E', 14, GPIO_IN, TIM1_REMAP2)>;
			};

			/omit-if-no-ref/ tim2_ch1_pwm_in_pa0: tim2_ch1_pwm_in_pa0 {
				pinmux = <STM32F1_PINMUX('A', 0, GPIO_IN, TIM2_REMAP0)>;
			};

			/omit-if-no-ref/ tim2_ch1_remap2_pwm_in_pa0: tim2_ch1_remap2_pwm_in_pa0 {
				pinmux = <STM32F1_PINMUX('A', 0, GPIO_IN, TIM2_REMAP2)>;
			};

			/omit-if-no-ref/ tim2_ch2_pwm_in_pa1: tim2_ch2_pwm_in_pa1 {
				pinmux = <STM32F1_PINMUX('A', 1, GPIO_IN, TIM2_REMAP0)>;
			};

			/omit-if-no-ref/ tim2_ch2_remap2_pwm_in_pa1: tim2_ch2_remap2_pwm_in_pa1 {
				pinmux = <STM32F1_PINMUX('A', 1, GPIO_IN, TIM2_REMAP2)>;
			};

			/omit-if-no-ref/ tim2_ch3_pwm_in_pa2: tim2_ch3_pwm_in_pa2 {
				pinmux = <STM32F1_PINMUX('A', 2, GPIO_IN, TIM2_REMAP0)>;
			};

			/omit-if-no-ref/ tim2_ch3_remap1_pwm_in_pa2: tim2_ch3_remap1_pwm_in_pa2 {
				pinmux = <STM32F1_PINMUX('A', 2, GPIO_IN, TIM2_REMAP1)>;
			};

			/omit-if-no-ref/ tim2_ch4_pwm_in_pa3: tim2_ch4_pwm_in_pa3 {
				pinmux = <STM32F1_PINMUX('A', 3, GPIO_IN, TIM2_REMAP0)>;
			};

			/omit-if-no-ref/ tim2_ch4_remap1_pwm_in_pa3: tim2_ch4_remap1_pwm_in_pa3 {
				pinmux = <STM32F1_PINMUX('A', 3, GPIO_IN, TIM2_REMAP1)>;
			};

			/omit-if-no-ref/ tim2_ch1_remap1_pwm_in_pa15: tim2_ch1_remap1_pwm_in_pa15 {
				pinmux = <STM32F1_PINMUX('A', 15, GPIO_IN, TIM2_REMAP1)>;
			};

			/omit-if-no-ref/ tim2_ch1_remap3_pwm_in_pa15: tim2_ch1_remap3_pwm_in_pa15 {
				pinmux = <STM32F1_PINMUX('A', 15, GPIO_IN, TIM2_REMAP3)>;
			};

			/omit-if-no-ref/ tim2_ch2_remap1_pwm_in_pb3: tim2_ch2_remap1_pwm_in_pb3 {
				pinmux = <STM32F1_PINMUX('B', 3, GPIO_IN, TIM2_REMAP1)>;
			};

			/omit-if-no-ref/ tim2_ch2_remap3_pwm_in_pb3: tim2_ch2_remap3_pwm_in_pb3 {
				pinmux = <STM32F1_PINMUX('B', 3, GPIO_IN, TIM2_REMAP3)>;
			};

			/omit-if-no-ref/ tim2_ch3_remap2_pwm_in_pb10: tim2_ch3_remap2_pwm_in_pb10 {
				pinmux = <STM32F1_PINMUX('B', 10, GPIO_IN, TIM2_REMAP2)>;
			};

			/omit-if-no-ref/ tim2_ch3_remap3_pwm_in_pb10: tim2_ch3_remap3_pwm_in_pb10 {
				pinmux = <STM32F1_PINMUX('B', 10, GPIO_IN, TIM2_REMAP3)>;
			};

			/omit-if-no-ref/ tim2_ch4_remap2_pwm_in_pb11: tim2_ch4_remap2_pwm_in_pb11 {
				pinmux = <STM32F1_PINMUX('B', 11, GPIO_IN, TIM2_REMAP2)>;
			};

			/omit-if-no-ref/ tim2_ch4_remap3_pwm_in_pb11: tim2_ch4_remap3_pwm_in_pb11 {
				pinmux = <STM32F1_PINMUX('B', 11, GPIO_IN, TIM2_REMAP3)>;
			};

			/omit-if-no-ref/ tim3_ch1_pwm_in_pa6: tim3_ch1_pwm_in_pa6 {
				pinmux = <STM32F1_PINMUX('A', 6, GPIO_IN, TIM3_REMAP0)>;
			};

			/omit-if-no-ref/ tim3_ch2_pwm_in_pa7: tim3_ch2_pwm_in_pa7 {
				pinmux = <STM32F1_PINMUX('A', 7, GPIO_IN, TIM3_REMAP0)>;
			};

			/omit-if-no-ref/ tim3_ch3_pwm_in_pb0: tim3_ch3_pwm_in_pb0 {
				pinmux = <STM32F1_PINMUX('B', 0, GPIO_IN, TIM3_REMAP0)>;
			};

			/omit-if-no-ref/ tim3_ch3_remap1_pwm_in_pb0: tim3_ch3_remap1_pwm_in_pb0 {
				pinmux = <STM32F1_PINMUX('B', 0, GPIO_IN, TIM3_REMAP1)>;
			};

			/omit-if-no-ref/ tim3_ch4_pwm_in_pb1: tim3_ch4_pwm_in_pb1 {
				pinmux = <STM32F1_PINMUX('B', 1, GPIO_IN, TIM3_REMAP0)>;
			};

			/omit-if-no-ref/ tim3_ch4_remap1_pwm_in_pb1: tim3_ch4_remap1_pwm_in_pb1 {
				pinmux = <STM32F1_PINMUX('B', 1, GPIO_IN, TIM3_REMAP1)>;
			};

			/omit-if-no-ref/ tim3_ch1_remap1_pwm_in_pb4: tim3_ch1_remap1_pwm_in_pb4 {
				pinmux = <STM32F1_PINMUX('B', 4, GPIO_IN, TIM3_REMAP1)>;
			};

			/omit-if-no-ref/ tim3_ch2_remap1_pwm_in_pb5: tim3_ch2_remap1_pwm_in_pb5 {
				pinmux = <STM32F1_PINMUX('B', 5, GPIO_IN, TIM3_REMAP1)>;
			};

			/omit-if-no-ref/ tim3_ch1_remap2_pwm_in_pc6: tim3_ch1_remap2_pwm_in_pc6 {
				pinmux = <STM32F1_PINMUX('C', 6, GPIO_IN, TIM3_REMAP2)>;
			};

			/omit-if-no-ref/ tim3_ch2_remap2_pwm_in_pc7: tim3_ch2_remap2_pwm_in_pc7 {
				pinmux = <STM32F1_PINMUX('C', 7, GPIO_IN, TIM3_REMAP2)>;
			};

			/omit-if-no-ref/ tim3_ch3_remap2_pwm_in_pc8: tim3_ch3_remap2_pwm_in_pc8 {
				pinmux = <STM32F1_PINMUX('C', 8, GPIO_IN, TIM3_REMAP2)>;
			};

			/omit-if-no-ref/ tim3_ch4_remap2_pwm_in_pc9: tim3_ch4_remap2_pwm_in_pc9 {
				pinmux = <STM32F1_PINMUX('C', 9, GPIO_IN, TIM3_REMAP2)>;
			};

			/omit-if-no-ref/ tim4_ch1_pwm_in_pb6: tim4_ch1_pwm_in_pb6 {
				pinmux = <STM32F1_PINMUX('B', 6, GPIO_IN, TIM4_REMAP0)>;
			};

			/omit-if-no-ref/ tim4_ch2_pwm_in_pb7: tim4_ch2_pwm_in_pb7 {
				pinmux = <STM32F1_PINMUX('B', 7, GPIO_IN, TIM4_REMAP0)>;
			};

			/omit-if-no-ref/ tim4_ch3_pwm_in_pb8: tim4_ch3_pwm_in_pb8 {
				pinmux = <STM32F1_PINMUX('B', 8, GPIO_IN, TIM4_REMAP0)>;
			};

			/omit-if-no-ref/ tim4_ch4_pwm_in_pb9: tim4_ch4_pwm_in_pb9 {
				pinmux = <STM32F1_PINMUX('B', 9, GPIO_IN, TIM4_REMAP0)>;
			};

			/omit-if-no-ref/ tim4_ch1_remap1_pwm_in_pd12: tim4_ch1_remap1_pwm_in_pd12 {
				pinmux = <STM32F1_PINMUX('D', 12, GPIO_IN, TIM4_REMAP1)>;
			};

			/omit-if-no-ref/ tim4_ch2_remap1_pwm_in_pd13: tim4_ch2_remap1_pwm_in_pd13 {
				pinmux = <STM32F1_PINMUX('D', 13, GPIO_IN, TIM4_REMAP1)>;
			};

			/omit-if-no-ref/ tim4_ch3_remap1_pwm_in_pd14: tim4_ch3_remap1_pwm_in_pd14 {
				pinmux = <STM32F1_PINMUX('D', 14, GPIO_IN, TIM4_REMAP1)>;
			};

			/omit-if-no-ref/ tim4_ch4_remap1_pwm_in_pd15: tim4_ch4_remap1_pwm_in_pd15 {
				pinmux = <STM32F1_PINMUX('D', 15, GPIO_IN, TIM4_REMAP1)>;
			};

			/omit-if-no-ref/ tim5_ch1_pwm_in_pa0: tim5_ch1_pwm_in_pa0 {
				pinmux = <STM32F1_PINMUX('A', 0, GPIO_IN, NO_REMAP)>;
			};

			/omit-if-no-ref/ tim5_ch2_pwm_in_pa1: tim5_ch2_pwm_in_pa1 {
				pinmux = <STM32F1_PINMUX('A', 1, GPIO_IN, NO_REMAP)>;
			};

			/omit-if-no-ref/ tim5_ch3_pwm_in_pa2: tim5_ch3_pwm_in_pa2 {
				pinmux = <STM32F1_PINMUX('A', 2, GPIO_IN, NO_REMAP)>;
			};

			/omit-if-no-ref/ tim5_ch4_pwm_in_pa3: tim5_ch4_pwm_in_pa3 {
				pinmux = <STM32F1_PINMUX('A', 3, GPIO_IN, NO_REMAP)>;
			};

			/* TIM_CH_PWM_OUT / TIM_CHN_PWM_OUT */

			/omit-if-no-ref/ tim1_ch1n_remap1_pwm_out_pa7: tim1_ch1n_remap1_pwm_out_pa7 {
				pinmux = <STM32F1_PINMUX('A', 7, ALTERNATE, TIM1_REMAP1)>;
			};

			/omit-if-no-ref/ tim1_ch1_pwm_out_pa8: tim1_ch1_pwm_out_pa8 {
				pinmux = <STM32F1_PINMUX('A', 8, ALTERNATE, TIM1_REMAP0)>;
			};

			/omit-if-no-ref/ tim1_ch1_remap1_pwm_out_pa8: tim1_ch1_remap1_pwm_out_pa8 {
				pinmux = <STM32F1_PINMUX('A', 8, ALTERNATE, TIM1_REMAP1)>;
			};

			/omit-if-no-ref/ tim1_ch2_pwm_out_pa9: tim1_ch2_pwm_out_pa9 {
				pinmux = <STM32F1_PINMUX('A', 9, ALTERNATE, TIM1_REMAP0)>;
			};

			/omit-if-no-ref/ tim1_ch2_remap1_pwm_out_pa9: tim1_ch2_remap1_pwm_out_pa9 {
				pinmux = <STM32F1_PINMUX('A', 9, ALTERNATE, TIM1_REMAP1)>;
			};

			/omit-if-no-ref/ tim1_ch3_pwm_out_pa10: tim1_ch3_pwm_out_pa10 {
				pinmux = <STM32F1_PINMUX('A', 10, ALTERNATE, TIM1_REMAP0)>;
			};

			/omit-if-no-ref/ tim1_ch3_remap1_pwm_out_pa10: tim1_ch3_remap1_pwm_out_pa10 {
				pinmux = <STM32F1_PINMUX('A', 10, ALTERNATE, TIM1_REMAP1)>;
			};

			/omit-if-no-ref/ tim1_ch4_pwm_out_pa11: tim1_ch4_pwm_out_pa11 {
				pinmux = <STM32F1_PINMUX('A', 11, ALTERNATE, TIM1_REMAP0)>;
			};

			/omit-if-no-ref/ tim1_ch4_remap1_pwm_out_pa11: tim1_ch4_remap1_pwm_out_pa11 {
				pinmux = <STM32F1_PINMUX('A', 11, ALTERNATE, TIM1_REMAP1)>;
			};

			/omit-if-no-ref/ tim1_ch2n_remap1_pwm_out_pb0: tim1_ch2n_remap1_pwm_out_pb0 {
				pinmux = <STM32F1_PINMUX('B', 0, ALTERNATE, TIM1_REMAP1)>;
			};

			/omit-if-no-ref/ tim1_ch3n_remap1_pwm_out_pb1: tim1_ch3n_remap1_pwm_out_pb1 {
				pinmux = <STM32F1_PINMUX('B', 1, ALTERNATE, TIM1_REMAP1)>;
			};

			/omit-if-no-ref/ tim1_ch1n_pwm_out_pb13: tim1_ch1n_pwm_out_pb13 {
				pinmux = <STM32F1_PINMUX('B', 13, ALTERNATE, TIM1_REMAP0)>;
			};

			/omit-if-no-ref/ tim1_ch2n_pwm_out_pb14: tim1_ch2n_pwm_out_pb14 {
				pinmux = <STM32F1_PINMUX('B', 14, ALTERNATE, TIM1_REMAP0)>;
			};

			/omit-if-no-ref/ tim1_ch3n_pwm_out_pb15: tim1_ch3n_pwm_out_pb15 {
				pinmux = <STM32F1_PINMUX('B', 15, ALTERNATE, TIM1_REMAP0)>;
			};

			/omit-if-no-ref/ tim1_ch1n_remap2_pwm_out_pe8: tim1_ch1n_remap2_pwm_out_pe8 {
				pinmux = <STM32F1_PINMUX('E', 8, ALTERNATE, TIM1_REMAP2)>;
			};

			/omit-if-no-ref/ tim1_ch1_remap2_pwm_out_pe9: tim1_ch1_remap2_pwm_out_pe9 {
				pinmux = <STM32F1_PINMUX('E', 9, ALTERNATE, TIM1_REMAP2)>;
			};

			/omit-if-no-ref/ tim1_ch2n_remap2_pwm_out_pe10: tim1_ch2n_remap2_pwm_out_pe10 {
				pinmux = <STM32F1_PINMUX('E', 10, ALTERNATE, TIM1_REMAP2)>;
			};

			/omit-if-no-ref/ tim1_ch2_remap2_pwm_out_pe11: tim1_ch2_remap2_pwm_out_pe11 {
				pinmux = <STM32F1_PINMUX('E', 11, ALTERNATE, TIM1_REMAP2)>;
			};

			/omit-if-no-ref/ tim1_ch3n_remap2_pwm_out_pe12: tim1_ch3n_remap2_pwm_out_pe12 {
				pinmux = <STM32F1_PINMUX('E', 12, ALTERNATE, TIM1_REMAP2)>;
			};

			/omit-if-no-ref/ tim1_ch3_remap2_pwm_out_pe13: tim1_ch3_remap2_pwm_out_pe13 {
				pinmux = <STM32F1_PINMUX('E', 13, ALTERNATE, TIM1_REMAP2)>;
			};

			/omit-if-no-ref/ tim1_ch4_remap2_pwm_out_pe14: tim1_ch4_remap2_pwm_out_pe14 {
				pinmux = <STM32F1_PINMUX('E', 14, ALTERNATE, TIM1_REMAP2)>;
			};

			/omit-if-no-ref/ tim2_ch1_pwm_out_pa0: tim2_ch1_pwm_out_pa0 {
				pinmux = <STM32F1_PINMUX('A', 0, ALTERNATE, TIM2_REMAP0)>;
			};

			/omit-if-no-ref/ tim2_ch1_remap2_pwm_out_pa0: tim2_ch1_remap2_pwm_out_pa0 {
				pinmux = <STM32F1_PINMUX('A', 0, ALTERNATE, TIM2_REMAP2)>;
			};

			/omit-if-no-ref/ tim2_ch2_pwm_out_pa1: tim2_ch2_pwm_out_pa1 {
				pinmux = <STM32F1_PINMUX('A', 1, ALTERNATE, TIM2_REMAP0)>;
			};

			/omit-if-no-ref/ tim2_ch2_remap2_pwm_out_pa1: tim2_ch2_remap2_pwm_out_pa1 {
				pinmux = <STM32F1_PINMUX('A', 1, ALTERNATE, TIM2_REMAP2)>;
			};

			/omit-if-no-ref/ tim2_ch3_pwm_out_pa2: tim2_ch3_pwm_out_pa2 {
				pinmux = <STM32F1_PINMUX('A', 2, ALTERNATE, TIM2_REMAP0)>;
			};

			/omit-if-no-ref/ tim2_ch3_remap1_pwm_out_pa2: tim2_ch3_remap1_pwm_out_pa2 {
				pinmux = <STM32F1_PINMUX('A', 2, ALTERNATE, TIM2_REMAP1)>;
			};

			/omit-if-no-ref/ tim2_ch4_pwm_out_pa3: tim2_ch4_pwm_out_pa3 {
				pinmux = <STM32F1_PINMUX('A', 3, ALTERNATE, TIM2_REMAP0)>;
			};

			/omit-if-no-ref/ tim2_ch4_remap1_pwm_out_pa3: tim2_ch4_remap1_pwm_out_pa3 {
				pinmux = <STM32F1_PINMUX('A', 3, ALTERNATE, TIM2_REMAP1)>;
			};

			/omit-if-no-ref/ tim2_ch1_remap1_pwm_out_pa15: tim2_ch1_remap1_pwm_out_pa15 {
				pinmux = <STM32F1_PINMUX('A', 15, ALTERNATE, TIM2_REMAP1)>;
			};

			/omit-if-no-ref/ tim2_ch1_remap3_pwm_out_pa15: tim2_ch1_remap3_pwm_out_pa15 {
				pinmux = <STM32F1_PINMUX('A', 15, ALTERNATE, TIM2_REMAP3)>;
			};

			/omit-if-no-ref/ tim2_ch2_remap1_pwm_out_pb3: tim2_ch2_remap1_pwm_out_pb3 {
				pinmux = <STM32F1_PINMUX('B', 3, ALTERNATE, TIM2_REMAP1)>;
			};

			/omit-if-no-ref/ tim2_ch2_remap3_pwm_out_pb3: tim2_ch2_remap3_pwm_out_pb3 {
				pinmux = <STM32F1_PINMUX('B', 3, ALTERNATE, TIM2_REMAP3)>;
			};

			/omit-if-no-ref/ tim2_ch3_remap2_pwm_out_pb10: tim2_ch3_remap2_pwm_out_pb10 {
				pinmux = <STM32F1_PINMUX('B', 10, ALTERNATE, TIM2_REMAP2)>;
			};

			/omit-if-no-ref/ tim2_ch3_remap3_pwm_out_pb10: tim2_ch3_remap3_pwm_out_pb10 {
				pinmux = <STM32F1_PINMUX('B', 10, ALTERNATE, TIM2_REMAP3)>;
			};

			/omit-if-no-ref/ tim2_ch4_remap2_pwm_out_pb11: tim2_ch4_remap2_pwm_out_pb11 {
				pinmux = <STM32F1_PINMUX('B', 11, ALTERNATE, TIM2_REMAP2)>;
			};

			/omit-if-no-ref/ tim2_ch4_remap3_pwm_out_pb11: tim2_ch4_remap3_pwm_out_pb11 {
				pinmux = <STM32F1_PINMUX('B', 11, ALTERNATE, TIM2_REMAP3)>;
			};

			/omit-if-no-ref/ tim3_ch1_pwm_out_pa6: tim3_ch1_pwm_out_pa6 {
				pinmux = <STM32F1_PINMUX('A', 6, ALTERNATE, TIM3_REMAP0)>;
			};

			/omit-if-no-ref/ tim3_ch2_pwm_out_pa7: tim3_ch2_pwm_out_pa7 {
				pinmux = <STM32F1_PINMUX('A', 7, ALTERNATE, TIM3_REMAP0)>;
			};

			/omit-if-no-ref/ tim3_ch3_pwm_out_pb0: tim3_ch3_pwm_out_pb0 {
				pinmux = <STM32F1_PINMUX('B', 0, ALTERNATE, TIM3_REMAP0)>;
			};

			/omit-if-no-ref/ tim3_ch3_remap1_pwm_out_pb0: tim3_ch3_remap1_pwm_out_pb0 {
				pinmux = <STM32F1_PINMUX('B', 0, ALTERNATE, TIM3_REMAP1)>;
			};

			/omit-if-no-ref/ tim3_ch4_pwm_out_pb1: tim3_ch4_pwm_out_pb1 {
				pinmux = <STM32F1_PINMUX('B', 1, ALTERNATE, TIM3_REMAP0)>;
			};

			/omit-if-no-ref/ tim3_ch4_remap1_pwm_out_pb1: tim3_ch4_remap1_pwm_out_pb1 {
				pinmux = <STM32F1_PINMUX('B', 1, ALTERNATE, TIM3_REMAP1)>;
			};

			/omit-if-no-ref/ tim3_ch1_remap1_pwm_out_pb4: tim3_ch1_remap1_pwm_out_pb4 {
				pinmux = <STM32F1_PINMUX('B', 4, ALTERNATE, TIM3_REMAP1)>;
			};

			/omit-if-no-ref/ tim3_ch2_remap1_pwm_out_pb5: tim3_ch2_remap1_pwm_out_pb5 {
				pinmux = <STM32F1_PINMUX('B', 5, ALTERNATE, TIM3_REMAP1)>;
			};

			/omit-if-no-ref/ tim3_ch1_remap2_pwm_out_pc6: tim3_ch1_remap2_pwm_out_pc6 {
				pinmux = <STM32F1_PINMUX('C', 6, ALTERNATE, TIM3_REMAP2)>;
			};

			/omit-if-no-ref/ tim3_ch2_remap2_pwm_out_pc7: tim3_ch2_remap2_pwm_out_pc7 {
				pinmux = <STM32F1_PINMUX('C', 7, ALTERNATE, TIM3_REMAP2)>;
			};

			/omit-if-no-ref/ tim3_ch3_remap2_pwm_out_pc8: tim3_ch3_remap2_pwm_out_pc8 {
				pinmux = <STM32F1_PINMUX('C', 8, ALTERNATE, TIM3_REMAP2)>;
			};

			/omit-if-no-ref/ tim3_ch4_remap2_pwm_out_pc9: tim3_ch4_remap2_pwm_out_pc9 {
				pinmux = <STM32F1_PINMUX('C', 9, ALTERNATE, TIM3_REMAP2)>;
			};

			/omit-if-no-ref/ tim4_ch1_pwm_out_pb6: tim4_ch1_pwm_out_pb6 {
				pinmux = <STM32F1_PINMUX('B', 6, ALTERNATE, TIM4_REMAP0)>;
			};

			/omit-if-no-ref/ tim4_ch2_pwm_out_pb7: tim4_ch2_pwm_out_pb7 {
				pinmux = <STM32F1_PINMUX('B', 7, ALTERNATE, TIM4_REMAP0)>;
			};

			/omit-if-no-ref/ tim4_ch3_pwm_out_pb8: tim4_ch3_pwm_out_pb8 {
				pinmux = <STM32F1_PINMUX('B', 8, ALTERNATE, TIM4_REMAP0)>;
			};

			/omit-if-no-ref/ tim4_ch4_pwm_out_pb9: tim4_ch4_pwm_out_pb9 {
				pinmux = <STM32F1_PINMUX('B', 9, ALTERNATE, TIM4_REMAP0)>;
			};

			/omit-if-no-ref/ tim4_ch1_remap1_pwm_out_pd12: tim4_ch1_remap1_pwm_out_pd12 {
				pinmux = <STM32F1_PINMUX('D', 12, ALTERNATE, TIM4_REMAP1)>;
			};

			/omit-if-no-ref/ tim4_ch2_remap1_pwm_out_pd13: tim4_ch2_remap1_pwm_out_pd13 {
				pinmux = <STM32F1_PINMUX('D', 13, ALTERNATE, TIM4_REMAP1)>;
			};

			/omit-if-no-ref/ tim4_ch3_remap1_pwm_out_pd14: tim4_ch3_remap1_pwm_out_pd14 {
				pinmux = <STM32F1_PINMUX('D', 14, ALTERNATE, TIM4_REMAP1)>;
			};

			/omit-if-no-ref/ tim4_ch4_remap1_pwm_out_pd15: tim4_ch4_remap1_pwm_out_pd15 {
				pinmux = <STM32F1_PINMUX('D', 15, ALTERNATE, TIM4_REMAP1)>;
			};

			/omit-if-no-ref/ tim5_ch1_pwm_out_pa0: tim5_ch1_pwm_out_pa0 {
				pinmux = <STM32F1_PINMUX('A', 0, ALTERNATE, NO_REMAP)>;
			};

			/omit-if-no-ref/ tim5_ch2_pwm_out_pa1: tim5_ch2_pwm_out_pa1 {
				pinmux = <STM32F1_PINMUX('A', 1, ALTERNATE, NO_REMAP)>;
			};

			/omit-if-no-ref/ tim5_ch3_pwm_out_pa2: tim5_ch3_pwm_out_pa2 {
				pinmux = <STM32F1_PINMUX('A', 2, ALTERNATE, NO_REMAP)>;
			};

			/omit-if-no-ref/ tim5_ch4_pwm_out_pa3: tim5_ch4_pwm_out_pa3 {
				pinmux = <STM32F1_PINMUX('A', 3, ALTERNATE, NO_REMAP)>;
			};

			/* UART_CTS / USART_CTS */

			/omit-if-no-ref/ usart1_cts_pa11: usart1_cts_pa11 {
				pinmux = <STM32F1_PINMUX('A', 11, GPIO_IN, NO_REMAP)>;
				bias-pull-up;
				drive-open-drain;
			};

			/omit-if-no-ref/ usart2_cts_pa0: usart2_cts_pa0 {
				pinmux = <STM32F1_PINMUX('A', 0, GPIO_IN, USART2_REMAP0)>;
				bias-pull-up;
				drive-open-drain;
			};

			/omit-if-no-ref/ usart2_cts_remap1_pd3: usart2_cts_remap1_pd3 {
				pinmux = <STM32F1_PINMUX('D', 3, GPIO_IN, USART2_REMAP1)>;
				bias-pull-up;
				drive-open-drain;
			};

			/omit-if-no-ref/ usart3_cts_pb13: usart3_cts_pb13 {
				pinmux = <STM32F1_PINMUX('B', 13, GPIO_IN, USART3_REMAP0)>;
				bias-pull-up;
				drive-open-drain;
			};

			/omit-if-no-ref/ usart3_cts_remap1_pb13: usart3_cts_remap1_pb13 {
				pinmux = <STM32F1_PINMUX('B', 13, GPIO_IN, USART3_REMAP1)>;
				bias-pull-up;
				drive-open-drain;
			};

			/omit-if-no-ref/ usart3_cts_remap2_pd11: usart3_cts_remap2_pd11 {
				pinmux = <STM32F1_PINMUX('D', 11, GPIO_IN, USART3_REMAP2)>;
				bias-pull-up;
				drive-open-drain;
			};

			/* UART_RTS / USART_RTS */

			/omit-if-no-ref/ usart1_rts_pa12: usart1_rts_pa12 {
				pinmux = <STM32F1_PINMUX('A', 12, ALTERNATE, NO_REMAP)>;
			};

			/omit-if-no-ref/ usart2_rts_pa1: usart2_rts_pa1 {
				pinmux = <STM32F1_PINMUX('A', 1, ALTERNATE, USART2_REMAP0)>;
			};

			/omit-if-no-ref/ usart2_rts_remap1_pd4: usart2_rts_remap1_pd4 {
				pinmux = <STM32F1_PINMUX('D', 4, ALTERNATE, USART2_REMAP1)>;
			};

			/omit-if-no-ref/ usart3_rts_pb14: usart3_rts_pb14 {
				pinmux = <STM32F1_PINMUX('B', 14, ALTERNATE, USART3_REMAP0)>;
			};

			/omit-if-no-ref/ usart3_rts_remap1_pb14: usart3_rts_remap1_pb14 {
				pinmux = <STM32F1_PINMUX('B', 14, ALTERNATE, USART3_REMAP1)>;
			};

			/omit-if-no-ref/ usart3_rts_remap2_pd12: usart3_rts_remap2_pd12 {
				pinmux = <STM32F1_PINMUX('D', 12, ALTERNATE, USART3_REMAP2)>;
			};

			/* UART_RX / USART_RX */

			/omit-if-no-ref/ usart1_rx_pa10: usart1_rx_pa10 {
				pinmux = <STM32F1_PINMUX('A', 10, GPIO_IN, USART1_REMAP0)>;
			};

			/omit-if-no-ref/ usart1_rx_remap1_pb7: usart1_rx_remap1_pb7 {
				pinmux = <STM32F1_PINMUX('B', 7, GPIO_IN, USART1_REMAP1)>;
			};

			/omit-if-no-ref/ usart2_rx_pa3: usart2_rx_pa3 {
				pinmux = <STM32F1_PINMUX('A', 3, GPIO_IN, USART2_REMAP0)>;
			};

			/omit-if-no-ref/ usart2_rx_remap1_pd6: usart2_rx_remap1_pd6 {
				pinmux = <STM32F1_PINMUX('D', 6, GPIO_IN, USART2_REMAP1)>;
			};

			/omit-if-no-ref/ usart3_rx_pb11: usart3_rx_pb11 {
				pinmux = <STM32F1_PINMUX('B', 11, GPIO_IN, USART3_REMAP0)>;
			};

			/omit-if-no-ref/ usart3_rx_remap1_pc11: usart3_rx_remap1_pc11 {
				pinmux = <STM32F1_PINMUX('C', 11, GPIO_IN, USART3_REMAP1)>;
			};

			/omit-if-no-ref/ usart3_rx_remap2_pd9: usart3_rx_remap2_pd9 {
				pinmux = <STM32F1_PINMUX('D', 9, GPIO_IN, USART3_REMAP2)>;
			};

			/omit-if-no-ref/ uart4_rx_pc11: uart4_rx_pc11 {
				pinmux = <STM32F1_PINMUX('C', 11, GPIO_IN, NO_REMAP)>;
			};

			/omit-if-no-ref/ uart5_rx_pd2: uart5_rx_pd2 {
				pinmux = <STM32F1_PINMUX('D', 2, GPIO_IN, NO_REMAP)>;
			};

			/* UART_TX / USART_TX */

			/omit-if-no-ref/ usart1_tx_pa9: usart1_tx_pa9 {
				pinmux = <STM32F1_PINMUX('A', 9, ALTERNATE, USART1_REMAP0)>;
			};

			/omit-if-no-ref/ usart1_tx_remap1_pb6: usart1_tx_remap1_pb6 {
				pinmux = <STM32F1_PINMUX('B', 6, ALTERNATE, USART1_REMAP1)>;
			};

			/omit-if-no-ref/ usart2_tx_pa2: usart2_tx_pa2 {
				pinmux = <STM32F1_PINMUX('A', 2, ALTERNATE, USART2_REMAP0)>;
			};

			/omit-if-no-ref/ usart2_tx_remap1_pd5: usart2_tx_remap1_pd5 {
				pinmux = <STM32F1_PINMUX('D', 5, ALTERNATE, USART2_REMAP1)>;
			};

			/omit-if-no-ref/ usart3_tx_pb10: usart3_tx_pb10 {
				pinmux = <STM32F1_PINMUX('B', 10, ALTERNATE, USART3_REMAP0)>;
			};

			/omit-if-no-ref/ usart3_tx_remap1_pc10: usart3_tx_remap1_pc10 {
				pinmux = <STM32F1_PINMUX('C', 10, ALTERNATE, USART3_REMAP1)>;
			};

			/omit-if-no-ref/ usart3_tx_remap2_pd8: usart3_tx_remap2_pd8 {
				pinmux = <STM32F1_PINMUX('D', 8, ALTERNATE, USART3_REMAP2)>;
			};

			/omit-if-no-ref/ uart4_tx_pc10: uart4_tx_pc10 {
				pinmux = <STM32F1_PINMUX('C', 10, ALTERNATE, NO_REMAP)>;
			};

			/omit-if-no-ref/ uart5_tx_pc12: uart5_tx_pc12 {
				pinmux = <STM32F1_PINMUX('C', 12, ALTERNATE, NO_REMAP)>;
			};

			/* USB_OTG_FS */

			/omit-if-no-ref/ usb_otg_fs_sof_pa8: usb_otg_fs_sof_pa8 {
				pinmux = <STM32F1_PINMUX('A', 8, GPIO_IN, NO_REMAP)>;
			};

			/omit-if-no-ref/ usb_otg_fs_vbus_pa9: usb_otg_fs_vbus_pa9 {
				pinmux = <STM32F1_PINMUX('A', 9, GPIO_IN, NO_REMAP)>;
			};

			/omit-if-no-ref/ usb_otg_fs_id_pa10: usb_otg_fs_id_pa10 {
				pinmux = <STM32F1_PINMUX('A', 10, GPIO_IN, NO_REMAP)>;
			};

			/omit-if-no-ref/ usb_otg_fs_dm_pa11: usb_otg_fs_dm_pa11 {
				pinmux = <STM32F1_PINMUX('A', 11, GPIO_IN, NO_REMAP)>;
			};

			/omit-if-no-ref/ usb_otg_fs_dp_pa12: usb_otg_fs_dp_pa12 {
				pinmux = <STM32F1_PINMUX('A', 12, GPIO_IN, NO_REMAP)>;
			};

		};
	};
};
